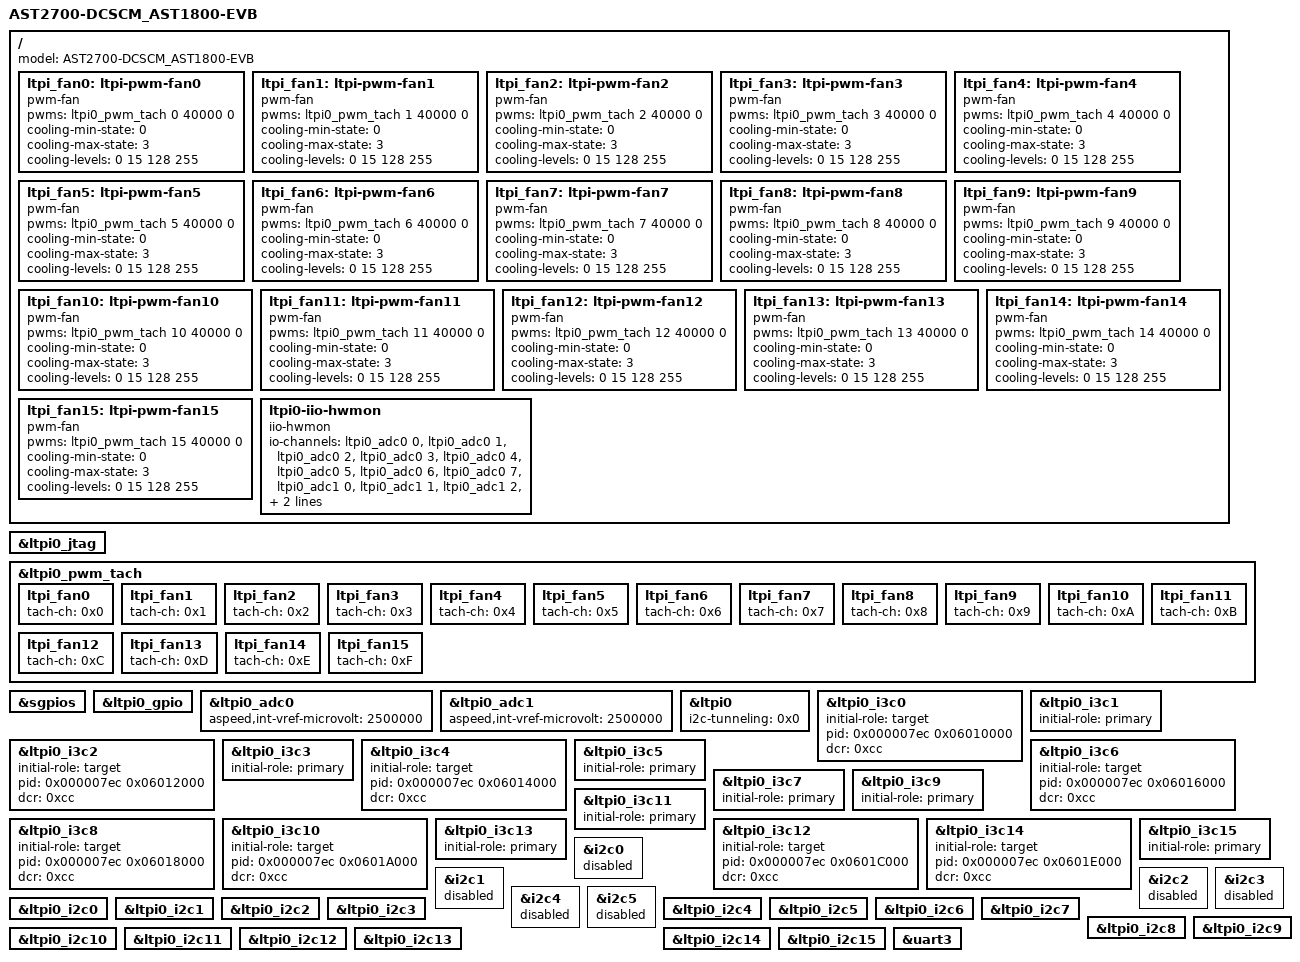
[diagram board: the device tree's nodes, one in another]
// SPDX-License-Identifier: GPL-2.0-or-later

/dts-v1/;

#include "ast2700-dcscm.dts"
#include "aspeed-ltpi1800.dtsi"

/ {
	model = "AST2700-DCSCM_AST1800-EVB";

	ltpi_fan0: ltpi-pwm-fan0 {
		compatible = "pwm-fan";
		pwms = <&ltpi0_pwm_tach 0 40000 0>;   /* Target freq:25 kHz */
		cooling-min-state = <0>;
		cooling-max-state = <3>;
		#cooling-cells = <2>;
		cooling-levels = <0 15 128 255>;
	};

	ltpi_fan1: ltpi-pwm-fan1 {
		compatible = "pwm-fan";
		pwms = <&ltpi0_pwm_tach 1 40000 0>;   /* Target freq:25 kHz */
		cooling-min-state = <0>;
		cooling-max-state = <3>;
		#cooling-cells = <2>;
		cooling-levels = <0 15 128 255>;
	};

	ltpi_fan2: ltpi-pwm-fan2 {
		compatible = "pwm-fan";
		pwms = <&ltpi0_pwm_tach 2 40000 0>;	/* Target freq:25 kHz */
		cooling-min-state = <0>;
		cooling-max-state = <3>;
		#cooling-cells = <2>;
		cooling-levels = <0 15 128 255>;
	};

	ltpi_fan3: ltpi-pwm-fan3 {
		compatible = "pwm-fan";
		pwms = <&ltpi0_pwm_tach 3 40000 0>;	/* Target freq:25 kHz */
		cooling-min-state = <0>;
		cooling-max-state = <3>;
		#cooling-cells = <2>;
		cooling-levels = <0 15 128 255>;
	};

	ltpi_fan4: ltpi-pwm-fan4 {
		compatible = "pwm-fan";
		pwms = <&ltpi0_pwm_tach 4 40000 0>;	/* Target freq:25 kHz */
		cooling-min-state = <0>;
		cooling-max-state = <3>;
		#cooling-cells = <2>;
		cooling-levels = <0 15 128 255>;
	};

	ltpi_fan5: ltpi-pwm-fan5 {
		compatible = "pwm-fan";
		pwms = <&ltpi0_pwm_tach 5 40000 0>;	/* Target freq:25 kHz */
		cooling-min-state = <0>;
		cooling-max-state = <3>;
		#cooling-cells = <2>;
		cooling-levels = <0 15 128 255>;
	};

	ltpi_fan6: ltpi-pwm-fan6 {
		compatible = "pwm-fan";
		pwms = <&ltpi0_pwm_tach 6 40000 0>;	/* Target freq:25 kHz */
		cooling-min-state = <0>;
		cooling-max-state = <3>;
		#cooling-cells = <2>;
		cooling-levels = <0 15 128 255>;
	};

	ltpi_fan7: ltpi-pwm-fan7 {
		compatible = "pwm-fan";
		pwms = <&ltpi0_pwm_tach 7 40000 0>;	/* Target freq:25 kHz */
		cooling-min-state = <0>;
		cooling-max-state = <3>;
		#cooling-cells = <2>;
		cooling-levels = <0 15 128 255>;
	};

	ltpi_fan8: ltpi-pwm-fan8 {
		compatible = "pwm-fan";
		pwms = <&ltpi0_pwm_tach 8 40000 0>;	/* Target freq:25 kHz */
		cooling-min-state = <0>;
		cooling-max-state = <3>;
		#cooling-cells = <2>;
		cooling-levels = <0 15 128 255>;
	};

	ltpi_fan9: ltpi-pwm-fan9 {
		compatible = "pwm-fan";
		pwms = <&ltpi0_pwm_tach 9 40000 0>;	/* Target freq:25 kHz */
		cooling-min-state = <0>;
		cooling-max-state = <3>;
		#cooling-cells = <2>;
		cooling-levels = <0 15 128 255>;
	};

	ltpi_fan10: ltpi-pwm-fan10 {
		compatible = "pwm-fan";
		pwms = <&ltpi0_pwm_tach 10 40000 0>;	/* Target freq:25 kHz */
		cooling-min-state = <0>;
		cooling-max-state = <3>;
		#cooling-cells = <2>;
		cooling-levels = <0 15 128 255>;
	};

	ltpi_fan11: ltpi-pwm-fan11 {
		compatible = "pwm-fan";
		pwms = <&ltpi0_pwm_tach 11 40000 0>;	/* Target freq:25 kHz */
		cooling-min-state = <0>;
		cooling-max-state = <3>;
		#cooling-cells = <2>;
		cooling-levels = <0 15 128 255>;
	};

	ltpi_fan12: ltpi-pwm-fan12 {
		compatible = "pwm-fan";
		pwms = <&ltpi0_pwm_tach 12 40000 0>;	/* Target freq:25 kHz */
		cooling-min-state = <0>;
		cooling-max-state = <3>;
		#cooling-cells = <2>;
		cooling-levels = <0 15 128 255>;
	};

	ltpi_fan13: ltpi-pwm-fan13 {
		compatible = "pwm-fan";
		pwms = <&ltpi0_pwm_tach 13 40000 0>;	/* Target freq:25 kHz */
		cooling-min-state = <0>;
		cooling-max-state = <3>;
		#cooling-cells = <2>;
		cooling-levels = <0 15 128 255>;
	};

	ltpi_fan14: ltpi-pwm-fan14 {
		compatible = "pwm-fan";
		pwms = <&ltpi0_pwm_tach 14 40000 0>;	/* Target freq:25 kHz */
		cooling-min-state = <0>;
		cooling-max-state = <3>;
		#cooling-cells = <2>;
		cooling-levels = <0 15 128 255>;
	};

	ltpi_fan15: ltpi-pwm-fan15 {
		compatible = "pwm-fan";
		pwms = <&ltpi0_pwm_tach 15 40000 0>;	/* Target freq:25 kHz */
		cooling-min-state = <0>;
		cooling-max-state = <3>;
		#cooling-cells = <2>;
		cooling-levels = <0 15 128 255>;
	};

	ltpi0-iio-hwmon {
		compatible = "iio-hwmon";
		io-channels = <&ltpi0_adc0 0>, <&ltpi0_adc0 1>, <&ltpi0_adc0 2>, <&ltpi0_adc0 3>,
				<&ltpi0_adc0 4>, <&ltpi0_adc0 5>, <&ltpi0_adc0 6>, <&ltpi0_adc0 7>,
				<&ltpi0_adc1 0>, <&ltpi0_adc1 1>, <&ltpi0_adc1 2>, <&ltpi0_adc1 3>,
				<&ltpi0_adc1 4>, <&ltpi0_adc1 5>, <&ltpi0_adc1 6>, <&ltpi0_adc1 7>;
	};
};

&ltpi0_jtag {
	status = "okay";
};

&ltpi0_pwm_tach {
	status = "okay";
	ltpi_fan0 {
		tach-ch = /bits/ 8 <0x0>;
	};
	ltpi_fan1 {
		tach-ch = /bits/ 8 <0x1>;
	};
	ltpi_fan2 {
		tach-ch = /bits/ 8 <0x2>;
	};
	ltpi_fan3 {
		tach-ch = /bits/ 8 <0x3>;
	};
	ltpi_fan4 {
		tach-ch = /bits/ 8 <0x4>;
	};
	ltpi_fan5 {
		tach-ch = /bits/ 8 <0x5>;
	};
	ltpi_fan6 {
		tach-ch = /bits/ 8 <0x6>;
	};
	ltpi_fan7 {
		tach-ch = /bits/ 8 <0x7>;
	};
	ltpi_fan8 {
		tach-ch = /bits/ 8 <0x8>;
	};
	ltpi_fan9 {
		tach-ch = /bits/ 8 <0x9>;
	};
	ltpi_fan10 {
		tach-ch = /bits/ 8 <0xA>;
	};
	ltpi_fan11 {
		tach-ch = /bits/ 8 <0xB>;
	};
	ltpi_fan12 {
		tach-ch = /bits/ 8 <0xC>;
	};
	ltpi_fan13 {
		tach-ch = /bits/ 8 <0xD>;
	};
	ltpi_fan14 {
		tach-ch = /bits/ 8 <0xE>;
	};
	ltpi_fan15 {
		tach-ch = /bits/ 8 <0xF>;
	};
};

&sgpios {
	/delete-property/ gpio-line-names;
};

&ltpi0_gpio {
	/delete-property/ gpio-line-names;
	/delete-node/ gpio_17;
	/delete-node/ gpio_19;
	/delete-node/ gpio_25;
	/delete-node/ gpio_53;
	/delete-node/ gpio_61;
	/delete-node/ gpio_63;
};

&ltpi0_adc0 {
	aspeed,int-vref-microvolt = <2500000>;
	status = "okay";
};

&ltpi0_adc1 {
	aspeed,int-vref-microvolt = <2500000>;
	status = "okay";
};

&ltpi0 {
	i2c-tunneling = <0x0>;
};

&ltpi0_i3c0 {
	initial-role = "target";
	pid = <0x000007ec 0x06010000>;
	dcr = /bits/ 8 <0xcc>;
	status = "okay";
};

&ltpi0_i3c1 {
	initial-role = "primary";
	status = "okay";
};

&ltpi0_i3c2 {
	initial-role = "target";
	pid = <0x000007ec 0x06012000>;
	dcr = /bits/ 8 <0xcc>;
	status = "okay";
};

&ltpi0_i3c3 {
	initial-role = "primary";
	status = "okay";
};

&ltpi0_i3c4 {
	initial-role = "target";
	pid = <0x000007ec 0x06014000>;
	dcr = /bits/ 8 <0xcc>;
	status = "okay";
};

&ltpi0_i3c5 {
	initial-role = "primary";
	status = "okay";
};

&ltpi0_i3c6 {
	initial-role = "target";
	pid = <0x000007ec 0x06016000>;
	dcr = /bits/ 8 <0xcc>;
	status = "okay";
};

&ltpi0_i3c7 {
	initial-role = "primary";
	status = "okay";
};

&ltpi0_i3c8 {
	initial-role = "target";
	pid = <0x000007ec 0x06018000>;
	dcr = /bits/ 8 <0xcc>;
	status = "okay";
};

&ltpi0_i3c9 {
	initial-role = "primary";
	status = "okay";
};

&ltpi0_i3c10 {
	initial-role = "target";
	pid = <0x000007ec 0x0601A000>;
	dcr = /bits/ 8 <0xcc>;
	status = "okay";
};

&ltpi0_i3c11 {
	initial-role = "primary";
	status = "okay";
};

&ltpi0_i3c12 {
	initial-role = "target";
	pid = <0x000007ec 0x0601C000>;
	dcr = /bits/ 8 <0xcc>;
	status = "okay";
};

&ltpi0_i3c13 {
	initial-role = "primary";
	status = "okay";
};

&ltpi0_i3c14 {
	initial-role = "target";
	pid = <0x000007ec 0x0601E000>;
	dcr = /bits/ 8 <0xcc>;
	status = "okay";
};

&ltpi0_i3c15 {
	initial-role = "primary";
	status = "okay";
};

&i2c0 {
	status = "disabled";
};

&i2c1 {
	status = "disabled";
};

&i2c2 {
	status = "disabled";
};

&i2c3 {
	status = "disabled";
};

&i2c4 {
	status = "disabled";
};

&i2c5 {
	status = "disabled";
};

&ltpi0_i2c0 {
	status = "okay";
};

&ltpi0_i2c1 {
	status = "okay";
};

&ltpi0_i2c2 {
	status = "okay";
};

&ltpi0_i2c3 {
	status = "okay";
};

&ltpi0_i2c4 {
	status = "okay";
};

&ltpi0_i2c5 {
	status = "okay";
};

&ltpi0_i2c6 {
	status = "okay";
};

&ltpi0_i2c7 {
	status = "okay";
};

&ltpi0_i2c8 {
	status = "okay";
};

&ltpi0_i2c9 {
	status = "okay";
};

&ltpi0_i2c10 {
	status = "okay";
};

&ltpi0_i2c11 {
	status = "okay";
};

&ltpi0_i2c12 {
	status = "okay";
};

&ltpi0_i2c13 {
	status = "okay";
};

&ltpi0_i2c14 {
	status = "okay";
};

&ltpi0_i2c15 {
	status = "okay";
};

&uart3 {
	/delete-property/ pinctrl-names;
	/delete-property/ pinctrl-0;
	status = "okay";
};
